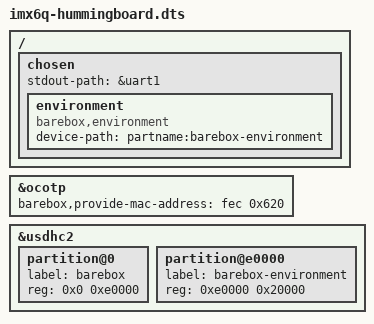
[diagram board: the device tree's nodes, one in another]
/*
 * Copyright (C) 2013 Russell King
 *
 * The code contained herein is licensed under the GNU General Public
 * License version 2.
 */

#include <arm/imx6q-hummingboard.dts>
#include "imx6qdl.dtsi"

/ {
	chosen {
		stdout-path = &uart1;

		environment {
			compatible = "barebox,environment";
			device-path = &usdhc2, "partname:barebox-environment";
		};
	};
};

&ocotp {
	barebox,provide-mac-address = <&fec 0x620>;
};

&usdhc2 {
	#address-cells = <1>;
	#size-cells = <1>;

	partition@0 {
		label = "barebox";
		reg = <0x0 0xe0000>;
	};

	partition@e0000 {
		label = "barebox-environment";
		reg = <0xe0000 0x20000>;
	};
};
